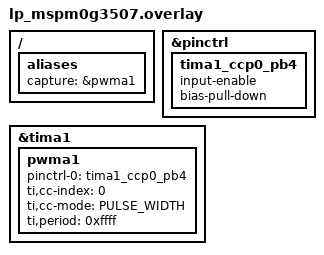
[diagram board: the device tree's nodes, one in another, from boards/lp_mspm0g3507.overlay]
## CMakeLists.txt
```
# SPDX-License-Identifier: Apache-2.0

cmake_minimum_required(VERSION 3.28.0)

find_package(Zephyr REQUIRED HINTS $ENV{ZEPHYR_BASE})
project(pwm_capture)

target_sources(app PRIVATE src/main.c)
```

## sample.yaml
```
sample:
  name: PWM capture
  description: input capture for PWM signal, time and duration application
common:
  tags:
    - drivers
    - pwm
  harness: console
  harness_config:
    type: multi_line
    ordered: true
    regex:
      - "timclk ([0-9]*) Hz"
      - "{period: ([0-9]*)  pulse width: ([0-9]*)} in TIMCLK cycle"
      - "{period: ([0-9]*) Hz duty: ([0-9]*)}"
  depends_on: pwm
tests:
  sample.drivers.pwm.capture:
    platform_allow:
      - lp_mspm0g3507
```

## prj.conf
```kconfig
CONFIG_PWM=y
CONFIG_PWM_CAPTURE=y
CONFIG_REQUIRES_FLOAT_PRINTF=y
```

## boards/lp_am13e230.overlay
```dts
/*
 * Copyright (c) 2026 Texas Instruments Incorporated
 *
 * SPDX-License-Identifier: Apache-2.0
 */

/ {
	aliases {
		capture = &ecap1;
	};
};
```

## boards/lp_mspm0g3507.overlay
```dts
/*
 * Copyright (c) 2025 Linumiz GmbH
 *
 * SPDX-License-Identifier: Apache-2.0
 */

/ {
	aliases {
		capture = &pwma1;
	};
};

&pinctrl {
	tima1_ccp0_pb4 {
		input-enable;
		bias-pull-down;
	};
};

&tima1 {
	status = "okay";

	pwma1: pwma1 {
		pinctrl-0 = <&tima1_ccp0_pb4>;
		pinctrl-names = "default";
		ti,cc-index = <0>;
		ti,cc-mode = "PULSE_WIDTH";
		ti,period = <0xffff>;
		status = "okay";
	};
};
```

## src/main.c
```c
/*
 * Copyright (c) 2025 Linumiz
 *
 * SPDX-License-Identifier: Apache-2.0
 */

#include <stdio.h>
#include <zephyr/kernel.h>
#include <zephyr/drivers/pwm.h>

int main(void)
{
	int ret;
	uint64_t tim_clk_cycles;
	const struct device *const dev = DEVICE_DT_GET(DT_ALIAS(capture));

	printk("PWM capture %s\n", CONFIG_BOARD_TARGET);
	if (!device_is_ready(dev)) {
		printk("device is not ready\n");
		return 0;
	}

	pwm_get_cycles_per_sec(dev, 0, &tim_clk_cycles);
	printk("timclk %llu Hz\n", tim_clk_cycles);

	while (1) {
		uint32_t period = 0;
		uint32_t width = 0;

		k_msleep(250);
		ret = pwm_capture_cycles(dev, 0,
					 (PWM_CAPTURE_TYPE_BOTH | PWM_CAPTURE_MODE_SINGLE),
					 &period, &width, Z_TIMEOUT_MS(500));

		if (ret == -EBUSY) {
			pwm_disable_capture(dev, 0);
			continue;
		}

		if (ret) {
			printk("capture cycle err %d\n", ret);
			continue;
		}

		printk("{period:%u  pulse width: %u} in TIMCLK cycle\n",
			period,
			width);

		printk("{period: %f Hz duty: %f}\n",
			(double)tim_clk_cycles / (double)period,
			(double)(width * 100) / (double)period);
	}

	return 0;
}
```
